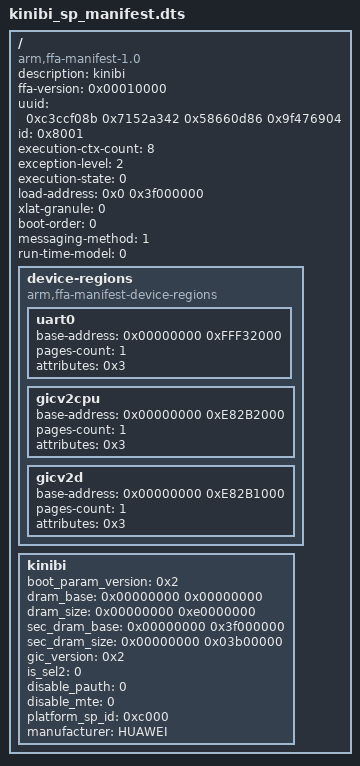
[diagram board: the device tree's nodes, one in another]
/*
 * Copyright (c) 2020-2022, Arm Limited. All rights reserved.
 *
 * SPDX-License-Identifier: BSD-3-Clause
 */
/dts-v1/;

/ {
	compatible = "arm,ffa-manifest-1.0";
	#address-cells = <2>;
	#size-cells = <1>;

	/* Properties */
	description = "kinibi";
	ffa-version = <0x00010000>; /* 31:16 - Major, 15:0 - Minor */
	uuid = <0xc3ccf08b 0x7152a342 0x58660d86 0x9f476904>;
	id = <0x8001>;
	execution-ctx-count = <8>;
	exception-level = <2>; /* S-EL1 */
	execution-state = <0>; /* AARCH64 */
	load-address = <0x0 0x3f000000>;
	/* entrypoint-offset = <0x1000>; */
	xlat-granule = <0>; /* 4KiB */
	boot-order = <0>;
	messaging-method = <1>; /* Direct messaging method */
	run-time-model = <0>; /* SP pre-emptible */

	device-regions {
		compatible = "arm,ffa-manifest-device-regions";

		uart0 {
			base-address = <0x00000000 0xFFF32000>;
			pages-count = <1>;
			attributes = <0x3>; /* read-write */
		};

		gicv2cpu {
			base-address = <0x00000000 0xE82B2000>;
			pages-count = <1>;
			attributes = <0x3>; /* read-write */
		};

		gicv2d {
			base-address = <0x00000000 0xE82B1000>;
			pages-count = <1>;
			attributes = <0x3>; /* read-write */
		};
	};

	/* Kinibi boot parameters */
	kinibi {
		boot_param_version = <0x2>;                 /* Version of the boot parameters */
		dram_base = <0x00000000 0x00000000>;        /* NonSecure DRAM start address */
		dram_size = <0x00000000 0xe0000000>;        /* NonSecure DRAM size */
		sec_dram_base = <0x00000000 0x3f000000>;    /* Secure DRAM start address */
		sec_dram_size = <0x00000000 0x03b00000>;    /* Secure DRAM size */
		gic_version = <0x2>;		/* GIC version */
		is_sel2 = <0>;			/* exception level flag */
		disable_pauth = <0>;		/* PAUTH (PAC/BTI) security features
						 *  <0> : features are enabled |
						 *  <1> : features are explicitly disabled
						 */
		disable_mte = <0>;		/* MTE security feature
						 *  <0> : feature is enabled |
						 *  <1> : feature is explicitly disabled
						 */
		platform_sp_id = <0xc000>;	/* Logical partition for Kinibi
						 * platform specific calls
						 */
		manufacturer = "HUAWEI";        /* Manufacturer name */
	};
};
